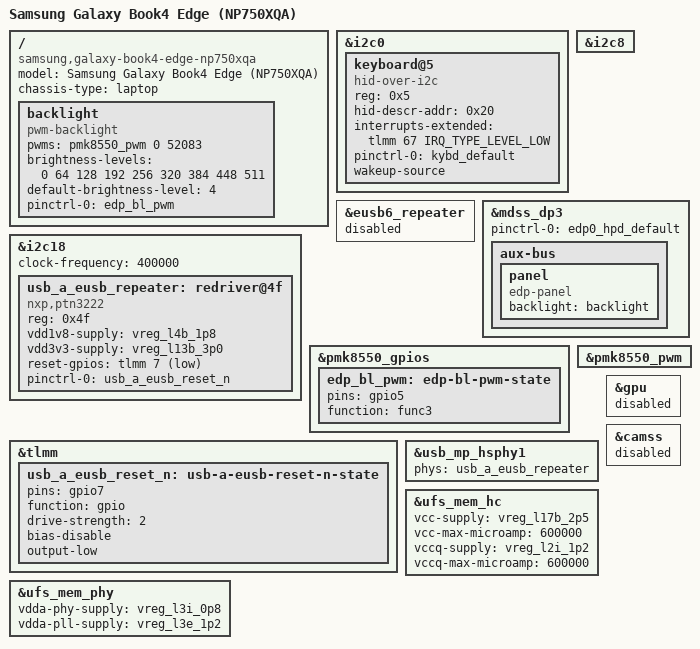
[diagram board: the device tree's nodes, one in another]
// SPDX-License-Identifier: BSD-3-Clause
/*
 * Initial Linux bring-up for the Samsung Galaxy Book4 Edge NP750XQA.
 *
 * The factory DSDT identifies the platform as SCP_PURWA / CRD08380, so the
 * Qualcomm X1P42100 CRD is the least-assumptive base for the first boot.
 */

/dts-v1/;

#include "x1p42100.dtsi"
#include "x1-crd.dtsi"

/delete-node/ &pmc8380_6;
/delete-node/ &pmc8380_6_thermal;

/ {
	model = "Samsung Galaxy Book4 Edge (NP750XQA)";
	compatible = "samsung,galaxy-book4-edge-np750xqa", "qcom,x1p42100";
	chassis-type = "laptop";

	backlight: backlight {
		compatible = "pwm-backlight";
		pwms = <&pmk8550_pwm 0 52083>;

		brightness-levels = <0 64 128 192 256 320 384 448 511>;
		default-brightness-level = <4>;

		pinctrl-0 = <&edp_bl_pwm>;
		pinctrl-names = "default";
	};
};

/* The CRD input devices are not fitted to this Samsung board. */
&i2c0 {
	/delete-node/ touchpad@15;
	/delete-node/ keyboard@3a;

	keyboard@5 {
		compatible = "hid-over-i2c";
		reg = <0x5>;

		hid-descr-addr = <0x20>;
		interrupts-extended = <&tlmm 67 IRQ_TYPE_LEVEL_LOW>;

		pinctrl-0 = <&kybd_default>;
		pinctrl-names = "default";

		wakeup-source;
	};
};

&i2c8 {
	/delete-node/ touchscreen@10;
};

/*
 * USB3/RHUB/MP1 is the external USB-A port used by the recovery stick. The
 * factory ACPI resources for USB3 (QCOM0D08 at 0x0a400000) place its two
 * eUSB2 repeaters on QUP_2_SE_2, which is i2c18 in the Linux DT numbering.
 * MP1 is the second USB2 port, so pair usb_mp_hsphy1 with the second ACPI
 * repeater resource: address 0x4f and TLMM GPIO 7.
 *
 * x1-crd.dtsi instead describes this repeater on i2c5 with GPIO 184. Keep
 * that CRD-only device from probing and override the inherited PHY link.
 */
&eusb6_repeater {
	status = "disabled";
};

&i2c18 {
	clock-frequency = <400000>;

	status = "okay";

	usb_a_eusb_repeater: redriver@4f {
		compatible = "nxp,ptn3222";
		reg = <0x4f>;
		#phy-cells = <0>;

		vdd1v8-supply = <&vreg_l4b_1p8>;
		vdd3v3-supply = <&vreg_l13b_3p0>;

		reset-gpios = <&tlmm 7 GPIO_ACTIVE_LOW>;

		pinctrl-0 = <&usb_a_eusb_reset_n>;
		pinctrl-names = "default";
	};
};

/*
 * The factory KDB KD156N2030A03 exposes a valid EDID and uses the standard
 * eDP AUX path. Replace the non-standard ATNA panel inherited from the CRD
 * with the generic eDP panel driver. The panel's ACPI profile reports an
 * active-high HPD signal and PMIC PWM backlight control at 19.2 kHz, matching
 * the dedicated DP3 HPD pin and PMK8550 PWM path used by Purwa designs.
 */
&mdss_dp3 {
	pinctrl-0 = <&edp0_hpd_default>;
	pinctrl-names = "default";

	status = "okay";

	aux-bus {
		panel {
			compatible = "edp-panel";
			/delete-property/ enable-gpios;
			/delete-property/ pinctrl-0;
			/delete-property/ pinctrl-names;

			backlight = <&backlight>;
		};
	};
};

&pmk8550_gpios {
	edp_bl_pwm: edp-bl-pwm-state {
		pins = "gpio5";
		function = "func3";
	};
};

&pmk8550_pwm {
	status = "okay";
};

&tlmm {
	usb_a_eusb_reset_n: usb-a-eusb-reset-n-state {
		pins = "gpio7";
		function = "gpio";
		drive-strength = <2>;
		bias-disable;
		output-low;
	};
};

&usb_mp_hsphy1 {
	phys = <&usb_a_eusb_repeater>;
};

/* Keep 3D acceleration out of the first display test; its firmware is absent. */
&gpu {
	status = "disabled";
};

/* The CRD camera sensor is not a description of the NP750XQA camera path. */
&camss {
	status = "disabled";
};

/* Internal Kioxia UFS storage, confirmed by ACPI QCOM24A5 at 0x01d84000. */
&ufs_mem_hc {
	status = "okay";

	vcc-supply = <&vreg_l17b_2p5>;
	vcc-max-microamp = <600000>;

	vccq-supply = <&vreg_l2i_1p2>;
	vccq-max-microamp = <600000>;
};

&ufs_mem_phy {
	status = "okay";

	vdda-phy-supply = <&vreg_l3i_0p8>;
	vdda-pll-supply = <&vreg_l3e_1p2>;
};
